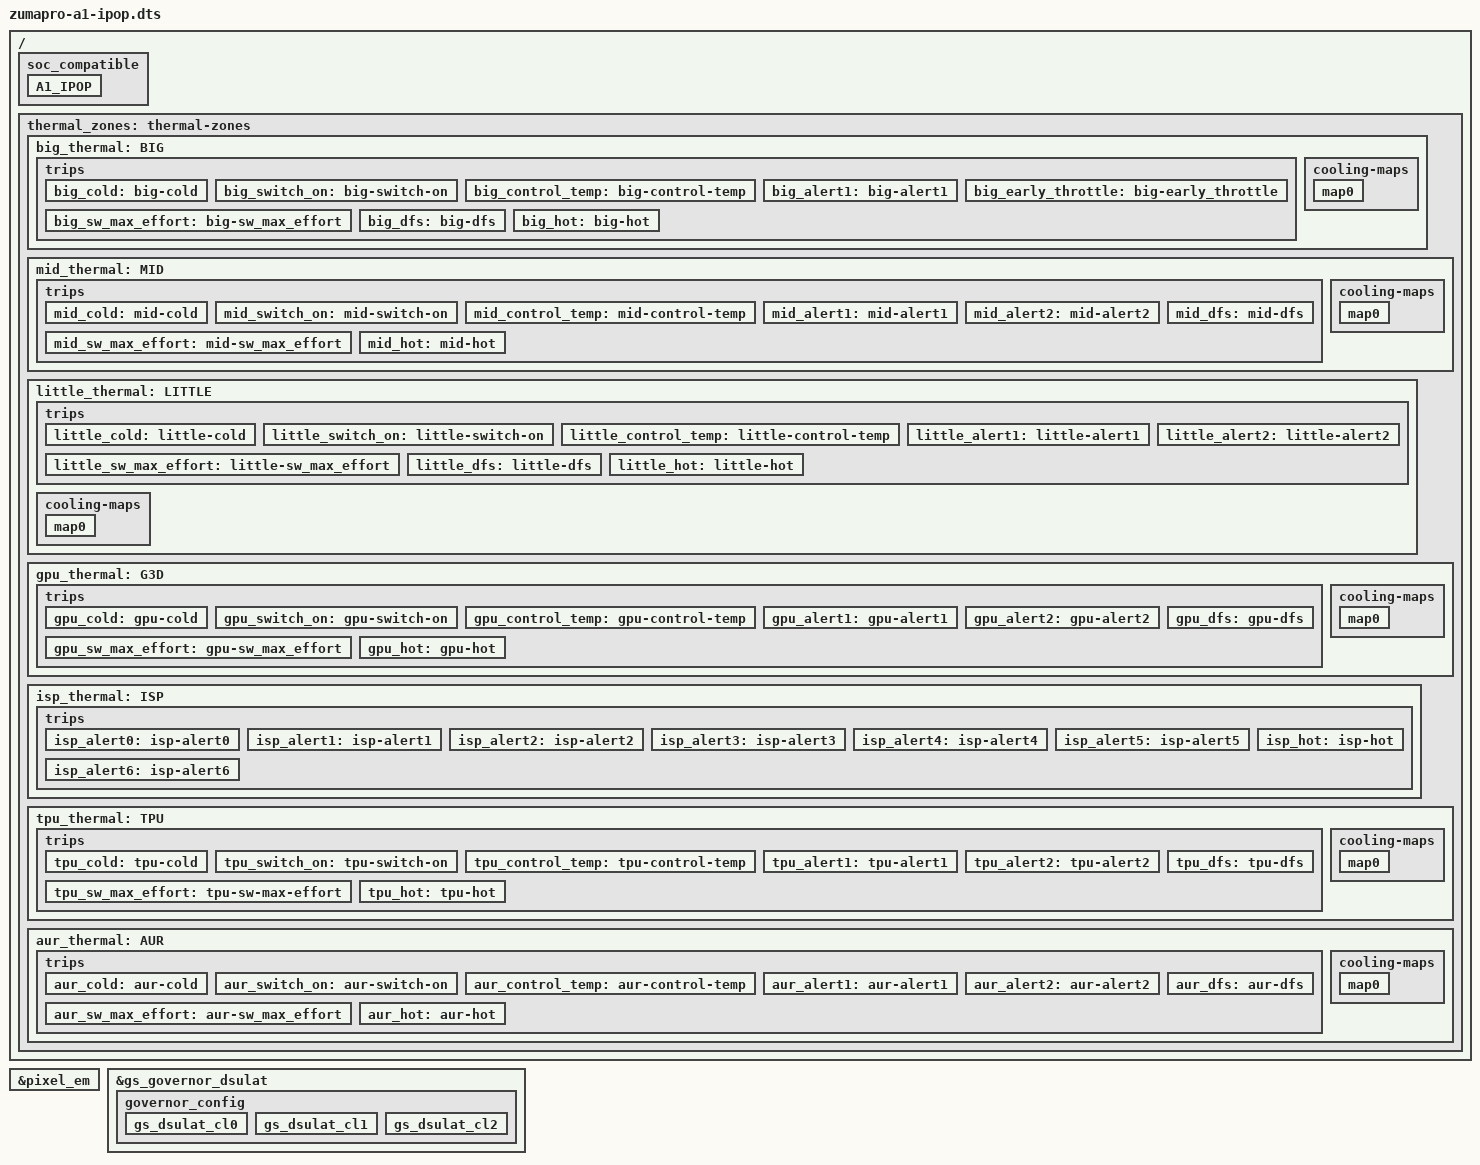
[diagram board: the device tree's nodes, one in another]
// SPDX-License-Identifier: GPL-2.0-only
/*
 * Copyright 2023 Google LLC.
 *
 */

/dts-v1/;

#include "zumapro-a0-ipop.dts"

/ {
	/* List of SoCs that this device tree is compatible with */
	soc_compatible {
		A1_IPOP {
			description = "A1,IPOP";
			product_id = <0x09875>;
			major = <0x0>;
			minor = <0x1>;
			pkg_mode = <0x1>;
		};
	};
};

/ {

	thermal_zones: thermal-zones {
		big_thermal: BIG {
			zone_name  = "BIG_THERMAL";
			polling-delay-passive = <0>;
			polling-delay = <0>;
			thermal-sensors = <&tmuctrl_0>;

			trips {
				big_cold: big-cold {
					temperature = <20000>; /* millicelsius */
					hysteresis = <5000>; /* millicelsius */
					type = "active";
				};
				big_switch_on: big-switch-on {
					temperature = <70000>; /* millicelsius */
					hysteresis = <5000>; /* millicelsius */
					type = "active";
				};
				big_control_temp: big-control-temp {
					temperature = <90000>; /* millicelsius */
					hysteresis = <5000>; /* millicelsius */
					type = "passive";
				};
				big_alert1: big-alert1 {
					temperature = <93000>; /* millicelsius */
					hysteresis = <93000>; /* 93C to avoid falling edge irq */
					type = "active";
				};
				big_early_throttle: big-early_throttle {
					temperature = <80000>; /* millicelsius */
					hysteresis = <5000>; /* millicelsius */
					type = "active";
				};
				big_sw_max_effort: big-sw_max_effort {
					temperature = <97000>; /* millicelsius */
					hysteresis = <2000>; /* millicelsius */
					type = "active";
				};
				big_dfs: big-dfs {
					temperature = <100000>; /* millicelsius */
					hysteresis = <5000>; /* millicelsius */
					type = "active";
				};
				big_hot: big-hot {
					temperature = <112000>; /* millicelsius */
					hysteresis = <3000>; /* millicelsius */
					type = "hot";
				};
			};
			cooling-maps {
				map0 {
					trip = <&big_control_temp>;
					cooling-device = <&cpufreq_domain2 0 0>;
				};
			};
		};
		mid_thermal: MID {
			zone_name  = "MID_THERMAL";
			polling-delay-passive = <0>;
			polling-delay = <0>;
			thermal-sensors = <&tmuctrl_1>;

			trips {
				mid_cold: mid-cold {
					temperature = <20000>; /* millicelsius */
					hysteresis = <5000>; /* millicelsius */
					type = "active";
				};
				mid_switch_on: mid-switch-on {
					temperature = <75000>; /* millicelsius */
					hysteresis = <5000>; /* millicelsius */
					type = "active";
				};
				mid_control_temp: mid-control-temp {
					temperature = <95000>; /* millicelsius */
					hysteresis = <5000>; /* millicelsius */
					type = "passive";
				};
				mid_alert1: mid-alert1 {
					temperature = <97000>; /* millicelsius */
					hysteresis = <93000>; /* 93C to avoid falling edge irq */
					type = "active";
				};
				mid_alert2: mid-alert2 {
					temperature = <99000>; /* millicelsius */
					hysteresis = <5000>; /* millicelsius */
					type = "passive";
				};
				mid_sw_max_effort: mid-sw_max_effort {
					temperature = <101000>; /* millicelsius */
					hysteresis = <2000>; /* millicelsius */
					type = "active";
				};
				mid_dfs: mid-dfs {
					temperature = <105000>; /* millicelsius */
					hysteresis = <5000>; /* millicelsius */
					type = "active";
				};
				mid_hot: mid-hot {
					temperature = <112000>; /* millicelsius */
					hysteresis = <3000>; /* millicelsius */
					type = "hot";
				};
			};
			cooling-maps {
				map0 {
				     trip = <&mid_control_temp>;
				     cooling-device = <&cpufreq_domain1 0 0>;
			       };
			};
		};
		little_thermal: LITTLE {
			zone_name  = "LITTLE_THERMAL";
			polling-delay-passive = <0>;
			polling-delay = <0>;
			thermal-sensors = <&tmuctrl_2>;

			trips {
				little_cold: little-cold {
					temperature = <20000>; /* millicelsius */
					hysteresis = <5000>; /* millicelsius */
					type = "active";
				};
				little_switch_on: little-switch-on {
					temperature = <70000>; /* millicelsius */
					hysteresis = <5000>; /* millicelsius */
					type = "active";
				};
				little_control_temp: little-control-temp {
					temperature = <95000>; /* millicelsius */
					hysteresis = <5000>; /* millicelsius */
					type = "passive";
				};
				little_alert1: little-alert1 {
					temperature = <97000>; /* millicelsius */
					hysteresis = <97000>; /* 97C to avoid falling edge irq */
					type = "active";
				};
				little_alert2: little-alert2 {
					temperature = <98000>; /* millicelsius */
					hysteresis = <2000>; /* millicelsius */
					type = "passive";
				};
				little_sw_max_effort: little-sw_max_effort {
					temperature = <99000>; /* millicelsius */
					hysteresis = <1000>; /* millicelsius */
					type = "passive";
				};
				little_dfs: little-dfs {
					temperature = <105000>; /* millicelsius */
					hysteresis = <5000>; /* millicelsius */
					type = "active";
				};
				little_hot: little-hot {
					temperature = <112000>; /* millicelsius */
					hysteresis = <3000>; /* millicelsius */
					type = "hot";
				};
			};
			cooling-maps {
				map0 {
				     trip = <&little_control_temp>;
				     cooling-device = <&cpufreq_domain0 0 0>;
				};
			};
		};
		gpu_thermal: G3D {
			zone_name  = "G3D_THERMAL";
			polling-delay-passive = <0>;
			polling-delay = <0>;
			thermal-sensors = <&tmuctrl_3>;

			trips {
				gpu_cold: gpu-cold {
					temperature = <20000>; /* millicelsius */
					hysteresis = <5000>; /* millicelsius */
					type = "active";
				};
				gpu_switch_on: gpu-switch-on {
					temperature = <70000>; /* millicelsius */
					hysteresis = <5000>; /* millicelsius */
					type = "active";
				};
				gpu_control_temp: gpu-control-temp {
					temperature = <90000>; /* millicelsius */
					hysteresis = <5000>; /* millicelsius */
					type = "passive";
				};
				gpu_alert1: gpu-alert1 {
					temperature = <95000>; /* millicelsius */
					hysteresis = <4000>; /* millicelsius */
					type = "passive";
				};
				gpu_alert2: gpu-alert2 {
					temperature = <98000>; /* millicelsius */
					hysteresis = <98000>; /* 98C to avoid falling edge irq */
					type = "active";
				};
				gpu_sw_max_effort: gpu-sw_max_effort {
					temperature = <102000>; /* millicelsius */
					hysteresis = <2000>; /* millicelsius */
					type = "active";
				};
				gpu_dfs: gpu-dfs {
					temperature = <100000>; /* millicelsius */
					hysteresis = <5000>; /* millicelsius */
					type = "active";
				};
				gpu_hot: gpu-hot {
					temperature = <115000>; /* millicelsius */
					hysteresis = <3000>; /* millicelsius */
					type = "hot";
				};
			};
			cooling-maps {
				map0 {
					trip = <&gpu_control_temp>;
					cooling-device = <&mali
						THERMAL_NO_LIMIT
						THERMAL_NO_LIMIT>;
				};
			};
		};
		isp_thermal: ISP {
			zone_name  = "ISP_THERMAL";
			polling-delay-passive = <0>;
			polling-delay = <0>;
			thermal-sensors = <&tmuctrl_4>;

			trips {
				isp_alert0: isp-alert0 {
					temperature = <20000>; /* millicelsius */
					hysteresis = <5000>; /* millicelsius */
					type = "active";
				};
				isp_alert1: isp-alert1 {
					temperature = <70000>; /* millicelsius */
					hysteresis = <5000>; /* millicelsius */
					type = "active";
				};
				isp_alert2: isp-alert2 {
					temperature = <90000>; /* millicelsius */
					hysteresis = <5000>; /* millicelsius */
					type = "passive";
				};
				isp_alert3: isp-alert3 {
					temperature = <95000>; /* millicelsius */
					hysteresis = <4000>; /* millicelsius */
					type = "passive";
				};
				isp_alert4: isp-alert4 {
					temperature = <98000>; /* millicelsius */
					hysteresis = <98000>; /* 98C to avoid falling edge irq */
					type = "active";
				};
				isp_alert5: isp-alert5 {
					temperature = <102000>; /* millicelsius */
					hysteresis = <102000>; /* 102C to avoid falling edge irq */
					type = "active";
				};
				isp_alert6: isp-alert6 {
					temperature = <100000>; /* millicelsius */
					hysteresis = <100000>; /* 100C to avoid falling edge irq */
					type = "active";
				};
				isp_hot: isp-hot {
					temperature = <115000>; /* millicelsius */
					hysteresis = <3000>; /* millicelsius */
					type = "hot";
				};
			};
		};
		tpu_thermal: TPU {
			zone_name  = "TPU_THERMAL";
			polling-delay-passive = <0>;
			polling-delay = <0>;
			thermal-sensors = <&tmuctrl_5>;

			trips {
				tpu_cold: tpu-cold {
					temperature = <20000>; /* millicelsius */
					hysteresis = <5000>; /* millicelsius */
					type = "active";
				};
				tpu_switch_on: tpu-switch-on {
					temperature = <70000>; /* millicelsius */
					hysteresis = <5000>; /* millicelsius */
					type = "active";
				};
				tpu_control_temp: tpu-control-temp {
					temperature = <90000>; /* millicelsius */
					hysteresis = <5000>; /* millicelsius */
					type = "passive";
				};
				tpu_alert1: tpu-alert1 {
					temperature = <95000>; /* millicelsius */
					hysteresis = <4000>; /* millicelsius */
					type = "passive";
				};
				tpu_alert2: tpu-alert2 {
					temperature = <98000>; /* millicelsius */
					hysteresis = <98000>; /* 98C to avoid falling edge irq */
					type = "active";
				};
				tpu_sw_max_effort: tpu-sw-max-effort {
					temperature = <102000>; /* millicelsius */
					hysteresis = <2000>; /* millicelsius */
					type = "active";
				};
				tpu_dfs: tpu-dfs {
					temperature = <100000>; /* millicelsius */
					hysteresis = <5000>; /* millicelsius */
					type = "active";
				};
				tpu_hot: tpu-hot {
					temperature = <115000>; /* millicelsius */
					hysteresis = <3000>; /* millicelsius */
					type = "hot";
				};
			};
			cooling-maps {
				map0 {
					trip = <&tpu_control_temp>;
					cooling-device = <&tpu_cooling 0 0>;
				};
			};
		};
		aur_thermal: AUR {
			zone_name  = "AUR_THERMAL";
			polling-delay-passive = <0>;
			polling-delay = <0>;
			thermal-sensors = <&tmuctrl_6>;

			trips {
				aur_cold: aur-cold {
					temperature = <20000>; /* millicelsius */
					hysteresis = <5000>; /* millicelsius */
					type = "active";
				};
				aur_switch_on: aur-switch-on {
					temperature = <70000>; /* millicelsius */
					hysteresis = <5000>; /* millicelsius */
					type = "active";
				};
				aur_control_temp: aur-control-temp {
					temperature = <90000>; /* millicelsius */
					hysteresis = <5000>; /* millicelsius */
					type = "passive";
				};
				aur_alert1: aur-alert1 {
					temperature = <95000>; /* millicelsius */
					hysteresis = <4000>; /* millicelsius */
					type = "passive";
				};
				aur_alert2: aur-alert2 {
					temperature = <98000>; /* millicelsius */
					hysteresis = <98000>; /* 98C to avoid falling edge irq */
					type = "active";
				};
				aur_sw_max_effort: aur-sw_max_effort {
					temperature = <102000>; /* millicelsius */
					hysteresis = <2000>; /* millicelsius */
					type = "active";
				};
				aur_dfs: aur-dfs {
					temperature = <100000>; /* millicelsius */
					hysteresis = <5000>; /* millicelsius */
					type = "active";
				};
				aur_hot: aur-hot {
					temperature = <115000>; /* millicelsius */
					hysteresis = <3000>; /* millicelsius */
					type = "hot";
				};
			};
			cooling-maps {
				map0 {
					trip = <&aur_control_temp>;
					cooling-device = <&gxp_cooling 0 0>;
				};
			};
		};
	};
};

&pixel_em {
		profiles =
			"default
				cpu0 {
				324000 32 15000
				610000 60 28000
				820000 80 37000
				955000 94 39000
				1098000 108 42000
				1197000 117 43000
				1328000 130 58000
				1425000 140 69000
				1548000 152 83000
				1696000 166 102000
				1849000 181 133000
				1950000 191 163000
				}
				cpu4 {
				357000 102 54000
				578000 165 90000
				648000 184 103000
				787000 224 131000
				910000 259 154000
				1065000 304 195000
				1221000 348 241000
				1328000 378 273000
				1418000 404 309000
				1549000 441 370000
				1795000 512 510000
				1945000 555 634000
				2130000 607 795000
				2245000 640 909000
				2367000 675 1072000
				2450000 699 1189000
				2600000 741 1311000
				}
				cpu7 {
				700000 229 266000
				1164000 380 496000
				1396000 453 670000
				1557000 509 807000
				1745000 575 1020000
				1885000 608 1181000
				1999000 635 1317000
				2147000 704 1579000
				2294000 759 1874000
				2363000 774 2027000
				2499000 821 2380000
				2687000 901 3092000
				2802000 923 3503000
				2914000 960 4008000
				2943000 970 4150000
				2970000 979 4287000
				3015000 994 4525000
				3105000 1024 5041000
				}
			",
			"cam1
				cpu0 {
				324000 33 24000
				610000 63 39000
				820000 84 56000
				955000 100 73000
				1098000 113 86000
				1197000 123 98000
				1328000 136 116000
				1425000 152 141000
				1548000 159 158000
				1696000 175 198000
				1849000 189 242000
				1950000 201 289000
				}
				cpu4 {
				357000 118 56000
				578000 170 84000
				648000 205 105000
				787000 212 107000
				910000 268 148000
				1065000 318 201000
				1221000 359 251000
				1328000 405 304000
				1418000 439 356000
				1549000 456 405000
				1795000 478 439000
				1945000 540 596000
				2130000 588 743000
				2245000 629 930000
				2367000 661 1122000
				2450000 692 1314000
				2600000 721 1515000
				}
				cpu7 {
				700000 235 190000
				1164000 399 342000
				1396000 443 415000
				1557000 507 544000
				1745000 571 682000
				1885000 609 765000
				1999000 618 799000
				2147000 680 983000
				2294000 714 1134000
				2363000 748 1322000
				2499000 794 1481000
				2687000 850 1883000
				2802000 923 2377000
				2914000 972 2882000
				2943000 999 3465000
				2970000 1007 3954000
				3015000 1014 4200000
				3105000 1024 4500000
				}
			",
			"cam2
				cpu0 {
				324000 33 16000
				610000 63 30500
				820000 84 42000
				955000 100 54000
				1098000 113 204000
				1197000 123 266000
				1328000 136 318000
				1425000 177 356000
				1548000 189 406000
				1696000 198 466000
				1849000 208 528000
				1950000 213 568000
				}
				cpu4 {
				357000 79 41000
				578000 113 58000
				648000 137 66000
				787000 189 79000
				910000 230 95000
				1065000 242 118000
				1221000 252 280000
				1328000 270 318000
				1418000 293 358000
				1549000 304 418000
				1795000 319 528000
				1945000 360 598000
				2130000 392 758000
				2245000 419 898000
				2367000 441 1012000
				2450000 461 1156000
				2600000 600 1416000
				}
				cpu7 {
				700000 171 205000
				1164000 399 354000
				1396000 443 481000
				1557000 507 569000
				1745000 571 672000
				1885000 609 749000
				1999000 618 926000
				2147000 680 1157000
				2294000 714 1386000
				2363000 748 1527000
				2499000 794 1806000
				2687000 850 2192000
				2802000 923 2429000
				2914000 972 2658000
				2943000 999 2718000
				2970000 1007 2773000
				3015000 1014 2866000
				3105000 1024 3051000
				}
			",
			"cam3
				cpu0 {
				324000 33 18000
				610000 63 36000
				820000 84 53000
				955000 100 80000
				1098000 113 204000
				1197000 123 266000
				1328000 136 318000
				1425000 198 356000
				1548000 207 406000
				1696000 228 466000
				1849000 246 528000
				1950000 261 568000
				}
				cpu4 {
				357000 79 41000
				578000 113 58000
				648000 137 64000
				787000 189 79000
				910000 230 95000
				1065000 242 118000
				1221000 252 280000
				1328000 270 318000
				1418000 293 358000
				1549000 304 418000
				1795000 319 528000
				1945000 360 598000
				2130000 392 758000
				2245000 419 898000
				2367000 441 1012000
				2450000 461 1156000
				2600000 681 1416000
				}
				cpu7 {
				700000 233 206000
				1164000 399 354000
				1396000 443 481000
				1557000 507 569000
				1745000 571 672000
				1885000 609 749000
				1999000 618 926000
				2147000 680 1157000
				2294000 714 1386000
				2363000 748 1527000
				2499000 794 1806000
				2687000 850 2192000
				2802000 923 2429000
				2914000 972 2658000
				2943000 999 2718000
				2970000 1007 2773000
				3015000 1014 2866000
				3105000 1024 3051000
				}
			";
		idle_energy =
			"
			cpu0 {
			324000 320000
			610000 480000
			820000 480000
			955000 480000
			1098000 480000
			1197000 480000
			1328000 640000
			1425000 640000
			1548000 640000
			1696000 800000
			1849000 960000
			1950000 1280000
			}
			cpu4 {
			357000 1760000
			578000 2080000
			648000 1920000
			787000 2080000
			910000 2400000
			1065000 2560000
			1221000 2720000
			1328000 3040000
			1418000 3040000
			1549000 3520000
			1795000 4000000
			1945000 4480000
			2130000 6560000
			2245000 8000000
			2367000 9440000
			2450000 10880000
			2600000 12960000
			}
			cpu7 {
			700000 6240000
			1164000 9120000
			1396000 11840000
			1557000 12160000
			1745000 13760000
			1885000 15200000
			1999000 16160000
			2147000 19840000
			2294000 23360000
			2363000 28960000
			2499000 34400000
			2687000 36480000
			2802000 41600000
			2914000 45120000
			2943000 46720000
			2970000 47680000
			3015000 61280000
			3105000 62400000
			}
			";
};

&gs_governor_dsulat {
	governor_config {
		gs_dsulat_cl0 {
			core-dev-table-latency =
			/* CL0           DSU */
			<  324000        324000 >,
			<  467000        610000 >,
			<  820000        970000 >,
			<  955000       1197000 >,
			< 1098000       1328000 >;

			core-dev-table-base =
			/* CL0           DSU */
			<  324000        324000 >,
			< 1098000        610000 >;
		};
		gs_dsulat_cl1 {
			core-dev-table-latency =
			/* CL1           DSU */
			<  357000        610000 >,
			<  468000        970000 >,
			<  910000       1197000 >,
			< 1795000       1328000 >,
			< 1945000       1444000 >,
			< 2130000       1548000 >,
			< 2450000       2024000 >;

			core-dev-table-base =
			/* CL1           DSU */
			<  357000        324000 >,
			< 1418000        610000 >,
			< 1795000        970000 >,
			< 2130000       1098000 >;
		};
		gs_dsulat_cl2 {
			core-dev-table-latency =
			/* CL2           DSU */
			<  700000        610000 >,
			< 1164000        970000 >,
			< 1396000       1197000 >,
			< 1885000       1328000 >,
			< 2147000       1444000 >,
			< 2363000       1800000 >,
			< 2802000       2024000 >,
			< 2914000       2150000 >;

			core-dev-table-base =
			/* CL2           DSU */
			<  700000        324000 >,
			< 1396000        610000 >,
			< 2147000        970000 >,
			< 2363000       1098000 >,
			< 2802000       1444000 >;
		};
	};
};
